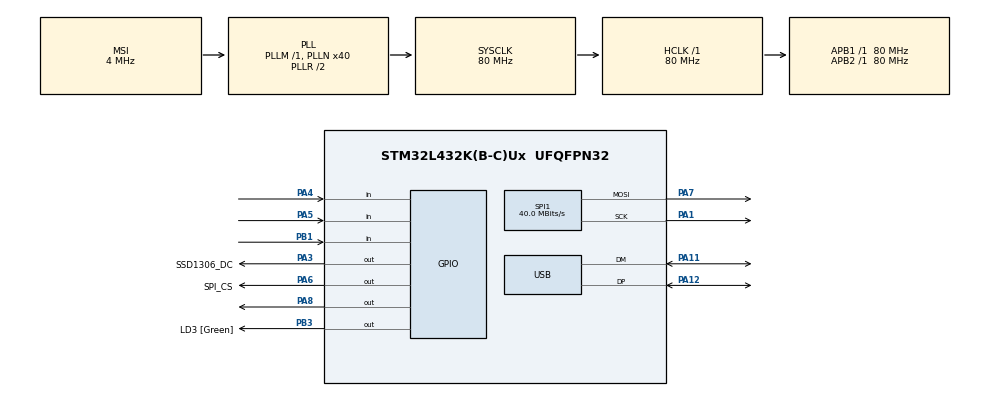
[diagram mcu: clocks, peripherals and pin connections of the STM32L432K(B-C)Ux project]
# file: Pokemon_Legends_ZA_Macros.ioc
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Mcu.Family=STM32L4
Mcu.Name=STM32L432K(B-C)Ux
Mcu.Package=UFQFPN32
NVIC.PriorityGroup=NVIC_PRIORITYGROUP_4
NVIC.TIM7_IRQn=true\:0\:0\:false\:false\:true\:true\:true\:true
NVIC.USB_IRQn=true\:0\:0\:false\:false\:true\:false\:true\:true
PA0.GPIO_Label=MCO [High speed clock in]
PA0.Signal=RCC_CK_IN
PA1.Mode=TX_Only_Simplex_Unidirect_Master
PA1.Signal=SPI1_SCK
PA11.Mode=Device
PA11.Signal=USB_DM
PA12.Mode=Device
PA12.Signal=USB_DP
PA13\ (JTMS-SWDIO).GPIO_Label=SWDIO
PA13\ (JTMS-SWDIO).Signal=SYS_JTMS-SWDIO
PA14\ (JTCK-SWCLK).GPIO_Label=SWCLK
PA14\ (JTCK-SWCLK).Signal=SYS_JTCK-SWCLK
PA15\ (JTDI).GPIO_Label=VCP_RX
PA15\ (JTDI).Signal=USART2_RX
PA2.GPIO_Label=VCP_TX
PA2.Signal=USART2_TX
PA3.GPIO_Label=SSD1306_DC
PA3.Signal=GPIO_Output
PA4.GPIO_PuPd=GPIO_PULLUP
PA4.Signal=GPIO_Input
PA5.GPIO_PuPd=GPIO_PULLUP
PA5.Signal=GPIO_Input
PA6.GPIO_Label=SPI_CS
PA6.PinState=GPIO_PIN_SET
PA6.Signal=GPIO_Output
PA7.Mode=TX_Only_Simplex_Unidirect_Master
PA7.Signal=SPI1_MOSI
PA8.Signal=GPIO_Output
PB1.GPIO_PuPd=GPIO_PULLUP
PB1.Signal=GPIO_Input
PB3\ (JTDO-TRACESWO).GPIO_Label=LD3 [Green]
PB3\ (JTDO-TRACESWO).Signal=GPIO_Output
PC14-OSC32_IN\ (PC14).Signal=RCC_OSC32_IN
PC15-OSC32_OUT\ (PC15).Signal=RCC_OSC32_OUT
ProjectManager.HeapSize=0x200
ProjectManager.StackSize=0x400
ProjectManager.TargetToolchain=STM32CubeIDE
RCC.ADCFreq_Value=48000000
RCC.AHBFreq_Value=80000000
RCC.APB1Freq_Value=80000000
RCC.APB1TimFreq_Value=80000000
RCC.APB2Freq_Value=80000000
RCC.APB2TimFreq_Value=80000000
RCC.CortexFreq_Value=80000000
RCC.HCLKFreq_Value=80000000
RCC.HSE_VALUE=8000000
RCC.HSI16_VALUE=16000000
RCC.HSI48_VALUE=48000000
RCC.HSI_VALUE=16000000
RCC.LSE_VALUE=32768
RCC.MSI_VALUE=4000000
RCC.PLLMUL=RCC_PLLMUL_4
RCC.PLLN=40
RCC.PLLSAI1N=24
RCC.SYSCLKFreq_VALUE=80000000
RCC.SYSCLKSource=RCC_SYSCLKSOURCE_PLLCLK
RCC.USBFreq_Value=48000000
RCC.VCOOutputFreq_Value=160000000
SPI1.CalculateBaudRate=40.0 MBits/s
SPI1.DataSize=SPI_DATASIZE_8BIT
SPI1.Direction=SPI_DIRECTION_2LINES
SPI1.Mode=SPI_MODE_MASTER
SPI1.VirtualType=VM_MASTER
TIM7.Period=250
TIM7.Prescaler=15
USB_DEVICE.CLASS_NAME_FS=HID
USB_DEVICE.VirtualMode=Hid
USB_DEVICE.VirtualModeFS=Hid_FS
VP_TIM7_VS_ClockSourceINT.Mode=Enable_Timer
VP_USB_DEVICE_VS_USB_DEVICE_HID_FS.Mode=HID_FS
board=NUCLEO-L432KC

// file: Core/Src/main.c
/* USER CODE BEGIN Header */
/**
  ******************************************************************************
  * @file           : main.c
  * @brief          : Main program body
  ******************************************************************************
  * @attention
  *
  * Copyright (c) 2025 STMicroelectronics.
  * All rights reserved.
  *
  * This software is licensed under terms that can be found in the LICENSE file
  * in the root directory of this software component.
  * If no LICENSE file comes with this software, it is provided AS-IS.
  *
  ******************************************************************************
  */
/* USER CODE END Header */
#include "main.h"
#include "usb_device.h"

/* USER CODE BEGIN Includes */
#include "usb_device.h"
void cpp_main();
/* USER CODE END Includes */

TIM_HandleTypeDef htim7;

void SystemClock_Config(void);
static void MX_GPIO_Init(void);
static void MX_SPI1_Init(void);
static void MX_TIM7_Init(void);

int main(void)
{

  /* MCU Configuration--------------------------------------------------------*/

  /* Reset of all peripherals, Initializes the Flash interface and the Systick. */
  HAL_Init();

  /* Configure the system clock */
  SystemClock_Config();

  /* Initialize all configured peripherals */
  MX_GPIO_Init();
  MX_USB_DEVICE_Init();
  MX_SPI1_Init();
  MX_TIM7_Init();
  /* USER CODE BEGIN 2 */
  HAL_TIM_Base_Start_IT(&htim7);
  /* USER CODE END 2 */

  /* Infinite loop */
  /* USER CODE BEGIN WHILE */
  cpp_main();
  while (1)
  {
    /* USER CODE END WHILE */

  }
}

void SystemClock_Config(void)
{
  RCC_OscInitTypeDef RCC_OscInitStruct = {0};
  RCC_ClkInitTypeDef RCC_ClkInitStruct = {0};

  /** Configure the main internal regulator output voltage
  */
  if (HAL_PWREx_ControlVoltageScaling(PWR_REGULATOR_VOLTAGE_SCALE1) != HAL_OK)
  {
    Error_Handler();
  }

  /** Initializes the RCC Oscillators according to the specified parameters
  * in the RCC_OscInitTypeDef structure.
  */
  RCC_OscInitStruct.OscillatorType = RCC_OSCILLATORTYPE_MSI;
  RCC_OscInitStruct.MSIState = RCC_MSI_ON;
  RCC_OscInitStruct.MSICalibrationValue = 0;
  RCC_OscInitStruct.MSIClockRange = RCC_MSIRANGE_6;
  RCC_OscInitStruct.PLL.PLLState = RCC_PLL_ON;
  RCC_OscInitStruct.PLL.PLLSource = RCC_PLLSOURCE_MSI;
  RCC_OscInitStruct.PLL.PLLM = 1;
  RCC_OscInitStruct.PLL.PLLN = 40;
  RCC_OscInitStruct.PLL.PLLP = RCC_PLLP_DIV7;
  RCC_OscInitStruct.PLL.PLLQ = RCC_PLLQ_DIV2;
  RCC_OscInitStruct.PLL.PLLR = RCC_PLLR_DIV2;
  if (HAL_RCC_OscConfig(&RCC_OscInitStruct) != HAL_OK)
  {
    Error_Handler();
  }

  /** Initializes the CPU, AHB and APB buses clocks
  */
  RCC_ClkInitStruct.ClockType = RCC_CLOCKTYPE_HCLK|RCC_CLOCKTYPE_SYSCLK
                              |RCC_CLOCKTYPE_PCLK1|RCC_CLOCKTYPE_PCLK2;
  RCC_ClkInitStruct.SYSCLKSource = RCC_SYSCLKSOURCE_PLLCLK;
  RCC_ClkInitStruct.AHBCLKDivider = RCC_SYSCLK_DIV1;
  RCC_ClkInitStruct.APB1CLKDivider = RCC_HCLK_DIV1;
  RCC_ClkInitStruct.APB2CLKDivider = RCC_HCLK_DIV1;

  if (HAL_RCC_ClockConfig(&RCC_ClkInitStruct, FLASH_LATENCY_4) != HAL_OK)
  {
    Error_Handler();
  }
}

static void MX_SPI1_Init(void)
{

  LL_SPI_InitTypeDef SPI_InitStruct = {0};

  LL_GPIO_InitTypeDef GPIO_InitStruct = {0};

  /* Peripheral clock enable */
  LL_APB2_GRP1_EnableClock(LL_APB2_GRP1_PERIPH_SPI1);

  LL_AHB2_GRP1_EnableClock(LL_AHB2_GRP1_PERIPH_GPIOA);
  /**SPI1 GPIO Configuration
  PA1   ------> SPI1_SCK
  PA7   ------> SPI1_MOSI
  */
  GPIO_InitStruct.Pin = LL_GPIO_PIN_1|LL_GPIO_PIN_7;
  GPIO_InitStruct.Mode = LL_GPIO_MODE_ALTERNATE;
  GPIO_InitStruct.Speed = LL_GPIO_SPEED_FREQ_VERY_HIGH;
  GPIO_InitStruct.OutputType = LL_GPIO_OUTPUT_PUSHPULL;
  GPIO_InitStruct.Pull = LL_GPIO_PULL_NO;
  GPIO_InitStruct.Alternate = LL_GPIO_AF_5;
  LL_GPIO_Init(GPIOA, &GPIO_InitStruct);

  /* SPI1 parameter configuration*/
  SPI_InitStruct.TransferDirection = LL_SPI_FULL_DUPLEX;
  SPI_InitStruct.Mode = LL_SPI_MODE_MASTER;
  SPI_InitStruct.DataWidth = LL_SPI_DATAWIDTH_8BIT;
  SPI_InitStruct.ClockPolarity = LL_SPI_POLARITY_LOW;
  SPI_InitStruct.ClockPhase = LL_SPI_PHASE_1EDGE;
  SPI_InitStruct.NSS = LL_SPI_NSS_SOFT;
  SPI_InitStruct.BaudRate = LL_SPI_BAUDRATEPRESCALER_DIV2;
  SPI_InitStruct.BitOrder = LL_SPI_MSB_FIRST;
  SPI_InitStruct.CRCCalculation = LL_SPI_CRCCALCULATION_DISABLE;
  SPI_InitStruct.CRCPoly = 7;
  LL_SPI_Init(SPI1, &SPI_InitStruct);
  LL_SPI_SetStandard(SPI1, LL_SPI_PROTOCOL_MOTOROLA);
  LL_SPI_EnableNSSPulseMgt(SPI1);

}

static void MX_TIM7_Init(void)
{

  TIM_MasterConfigTypeDef sMasterConfig = {0};

  htim7.Instance = TIM7;
  htim7.Init.Prescaler = 15;
  htim7.Init.CounterMode = TIM_COUNTERMODE_UP;
  htim7.Init.Period = 250;
  htim7.Init.AutoReloadPreload = TIM_AUTORELOAD_PRELOAD_DISABLE;
  if (HAL_TIM_Base_Init(&htim7) != HAL_OK)
  {
    Error_Handler();
  }
  sMasterConfig.MasterOutputTrigger = TIM_TRGO_RESET;
  sMasterConfig.MasterSlaveMode = TIM_MASTERSLAVEMODE_DISABLE;
  if (HAL_TIMEx_MasterConfigSynchronization(&htim7, &sMasterConfig) != HAL_OK)
  {
    Error_Handler();
  }

}

static void MX_GPIO_Init(void)
{
  LL_GPIO_InitTypeDef GPIO_InitStruct = {0};

  /* GPIO Ports Clock Enable */
  LL_AHB2_GRP1_EnableClock(LL_AHB2_GRP1_PERIPH_GPIOC);
  LL_AHB2_GRP1_EnableClock(LL_AHB2_GRP1_PERIPH_GPIOA);
  LL_AHB2_GRP1_EnableClock(LL_AHB2_GRP1_PERIPH_GPIOB);

  /**/
  LL_GPIO_ResetOutputPin(GPIOA, SSD1306_DC_Pin|LL_GPIO_PIN_8);

  /**/
  LL_GPIO_ResetOutputPin(LD3_GPIO_Port, LD3_Pin);

  /**/
  LL_GPIO_SetOutputPin(SPI_CS_GPIO_Port, SPI_CS_Pin);

  /**/
  GPIO_InitStruct.Pin = VCP_TX_Pin;
  GPIO_InitStruct.Mode = LL_GPIO_MODE_ALTERNATE;
  GPIO_InitStruct.Speed = LL_GPIO_SPEED_FREQ_VERY_HIGH;
  GPIO_InitStruct.OutputType = LL_GPIO_OUTPUT_PUSHPULL;
  GPIO_InitStruct.Pull = LL_GPIO_PULL_NO;
  GPIO_InitStruct.Alternate = LL_GPIO_AF_7;
  LL_GPIO_Init(VCP_TX_GPIO_Port, &GPIO_InitStruct);

  /**/
  GPIO_InitStruct.Pin = SSD1306_DC_Pin|SPI_CS_Pin|LL_GPIO_PIN_8;
  GPIO_InitStruct.Mode = LL_GPIO_MODE_OUTPUT;
  GPIO_InitStruct.Speed = LL_GPIO_SPEED_FREQ_LOW;
  GPIO_InitStruct.OutputType = LL_GPIO_OUTPUT_PUSHPULL;
  GPIO_InitStruct.Pull = LL_GPIO_PULL_NO;
  LL_GPIO_Init(GPIOA, &GPIO_InitStruct);

  /**/
  GPIO_InitStruct.Pin = LL_GPIO_PIN_4|LL_GPIO_PIN_5;
  GPIO_InitStruct.Mode = LL_GPIO_MODE_INPUT;
  GPIO_InitStruct.Pull = LL_GPIO_PULL_UP;
  LL_GPIO_Init(GPIOA, &GPIO_InitStruct);

  /**/
  GPIO_InitStruct.Pin = LL_GPIO_PIN_1;
  GPIO_InitStruct.Mode = LL_GPIO_MODE_INPUT;
  GPIO_InitStruct.Pull = LL_GPIO_PULL_UP;
  LL_GPIO_Init(GPIOB, &GPIO_InitStruct);

  /**/
  GPIO_InitStruct.Pin = VCP_RX_Pin;
  GPIO_InitStruct.Mode = LL_GPIO_MODE_ALTERNATE;
  GPIO_InitStruct.Speed = LL_GPIO_SPEED_FREQ_VERY_HIGH;
  GPIO_InitStruct.OutputType = LL_GPIO_OUTPUT_PUSHPULL;
  GPIO_InitStruct.Pull = LL_GPIO_PULL_NO;
  GPIO_InitStruct.Alternate = LL_GPIO_AF_3;
  LL_GPIO_Init(VCP_RX_GPIO_Port, &GPIO_InitStruct);

  /**/
  GPIO_InitStruct.Pin = LD3_Pin;
  GPIO_InitStruct.Mode = LL_GPIO_MODE_OUTPUT;
  GPIO_InitStruct.Speed = LL_GPIO_SPEED_FREQ_LOW;
  GPIO_InitStruct.OutputType = LL_GPIO_OUTPUT_PUSHPULL;
  GPIO_InitStruct.Pull = LL_GPIO_PULL_NO;
  LL_GPIO_Init(LD3_GPIO_Port, &GPIO_InitStruct);

}

void Error_Handler(void)
{
  __disable_irq();
  while (1)
  {
  }
}
